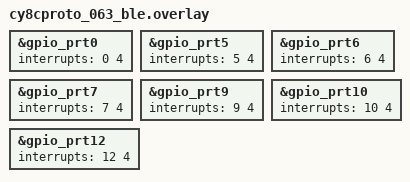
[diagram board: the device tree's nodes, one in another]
/*
 * Copyright (c) 2024 Cypress Semiconductor Corporation.
 * SPDX-License-Identifier: Apache-2.0
 */

/* Changed default interrupts priority for GPIO to 4 */
&gpio_prt0 {
	interrupts = <0 4>;
};

&gpio_prt5 {
	interrupts = <5 4>;
};

&gpio_prt6 {
	interrupts = <6 4>;
};

&gpio_prt7 {
	interrupts = <7 4>;
};

&gpio_prt9 {
	interrupts = <9 4>;
};

&gpio_prt10 {
	interrupts = <10 4>;
};

&gpio_prt12 {
	interrupts = <12 4>;
};
